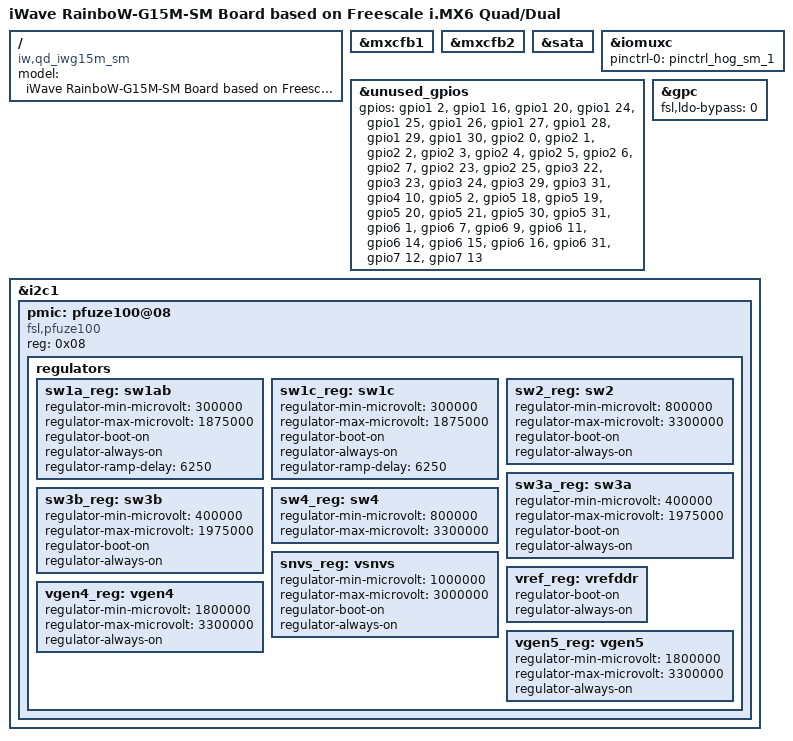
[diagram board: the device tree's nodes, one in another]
/*
 * Copyright (c) 2015 iWave Systems Technologies Pvt. Ltd.
 *
 * The code contained herein is licensed under the GNU General Public
 * License. You may obtain a copy of the GNU General Public License
 * Version 2 or later at the following locations:
 *
 * http://www.opensource.org/licenses/gpl-license.html
 * http://www.gnu.org/copyleft/gpl.html
 */

/dts-v1/;

#include "imx6q_iwg15.dtsi"
#include "imx6qdl-iwg15m-sm.dtsi"

/ {
	model = "iWave RainboW-G15M-SM Board based on Freescale i.MX6 Quad/Dual";
	compatible = "iw,qd_iwg15m_sm", "fsl,imx6q";
};

&mxcfb1 {
	status = "okay";
};

&mxcfb2 {
	status = "okay";
};

&sata {
        status = "okay";
};

&iomuxc {
        pinctrl-names = "default";
        pinctrl-0 = <&pinctrl_hog_sm_1>;
};

&unused_gpios {
        gpios = <
                &gpio1 2  0 &gpio1 16 0 &gpio1 20 0 
                &gpio1 24 0 &gpio1 25 0 &gpio1 26 0
                &gpio1 27 0 &gpio1 28 0 &gpio1 29 0
                &gpio1 30 0 &gpio2 0  0 &gpio2 1  0 
		&gpio2 2  0 &gpio2 3  0 &gpio2 4  0
  		&gpio2 5  0 &gpio2 6  0 &gpio2 7  0
		&gpio2 23 0 &gpio2 25 0 &gpio3 22 0
		&gpio3 23 0 &gpio3 24 0 &gpio3 29 0
		&gpio3 31 0 &gpio4 10 0 &gpio5 2  0 
		&gpio5 18 0 &gpio5 19 0 &gpio5 20 0 
		&gpio5 21 0 &gpio5 30 0 &gpio5 31 0 
		&gpio6 1  0 &gpio6 7  0	&gpio6 9  0 
		&gpio6 11 0 &gpio6 14 0	&gpio6 15 0 
		&gpio6 16 0 &gpio6 31 0 &gpio7 12 0	
		&gpio7 13 0
                >;
};

&gpc {
        fsl,ldo-bypass = <0>; /* use ldo-bypass, u-boot will check it and configure */
};

&i2c1 {
	pmic: pfuze100@08 {
		compatible = "fsl,pfuze100";
		reg = <0x08>;

		regulators {
			sw1a_reg: sw1ab {
				regulator-min-microvolt = <300000>;
				regulator-max-microvolt = <1875000>;
				regulator-boot-on;
				regulator-always-on;
				regulator-ramp-delay = <6250>;
			};

			sw1c_reg: sw1c {
				regulator-min-microvolt = <300000>;
				regulator-max-microvolt = <1875000>;
				regulator-boot-on;
				regulator-always-on;
				regulator-ramp-delay = <6250>;
			};

			sw2_reg: sw2 {
				regulator-min-microvolt = <800000>;
				regulator-max-microvolt = <3300000>;
				regulator-boot-on;
				regulator-always-on;
			};

			sw3a_reg: sw3a {
				regulator-min-microvolt = <400000>;
				regulator-max-microvolt = <1975000>;
				regulator-boot-on;
				regulator-always-on;
			};

			sw3b_reg: sw3b {
				regulator-min-microvolt = <400000>;
				regulator-max-microvolt = <1975000>;
				regulator-boot-on;
				regulator-always-on;
			};

			sw4_reg: sw4 {
				regulator-min-microvolt = <800000>;
				regulator-max-microvolt = <3300000>;
			};

			snvs_reg: vsnvs {
				regulator-min-microvolt = <1000000>;
				regulator-max-microvolt = <3000000>;
				regulator-boot-on;
				regulator-always-on;
			};

			vref_reg: vrefddr {
				regulator-boot-on;
				regulator-always-on;
			};

			vgen4_reg: vgen4 {
				regulator-min-microvolt = <1800000>;
				regulator-max-microvolt = <3300000>;
				regulator-always-on;
			};

			vgen5_reg: vgen5 {
				regulator-min-microvolt = <1800000>;
				regulator-max-microvolt = <3300000>;
				regulator-always-on;
			};

		};
	};
};
